# derived-from-bad-enumerated-values register map
Registers are 32-bit, access not given, reset 0x0 unless marked. A register's access mark holds for its fields unless they carry their own. Offsets are from the block's base; lines under a group give offsets from that group; [hi:lo] are bit positions; {n}, {i} and the like mark numbered series; 'fields as' and 'values as' point back to an identical list; <NAME> marks a mode.

## Memory map
0xDEADBEEF GPIOA

## GPIOA
Base 0xDEADBEEF
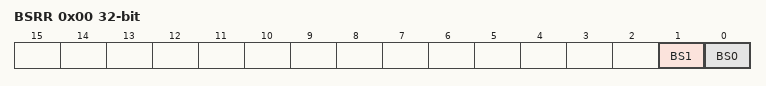
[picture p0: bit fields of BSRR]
0x00 BSRR — GPIO port bit set/reset register
  [1] BS1
  [0] BS0
    1=SET
